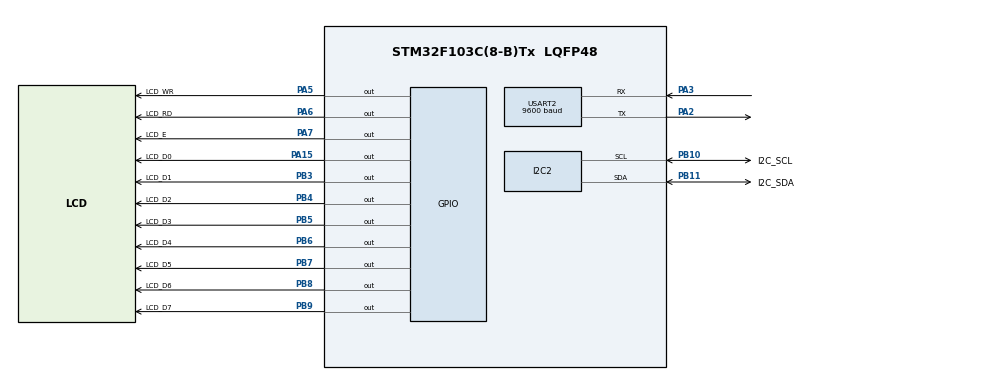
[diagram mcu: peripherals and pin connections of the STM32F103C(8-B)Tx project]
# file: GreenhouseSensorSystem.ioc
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Mcu.Family=STM32F1
Mcu.Name=STM32F103C(8-B)Tx
Mcu.Package=LQFP48
NVIC.PriorityGroup=NVIC_PRIORITYGROUP_4
NVIC.TIM1_UP_IRQn=true\:0\:0\:false\:false\:true\:false\:true
NVIC.TimeBase=TIM1_UP_IRQn
NVIC.TimeBaseIP=TIM1
PA15.GPIO_Label=LCD_D0
PA15.Signal=GPIO_Output
PA2.Mode=Asynchronous
PA2.Signal=USART2_TX
PA3.Mode=Asynchronous
PA3.Signal=USART2_RX
PA5.GPIO_Label=LCD_WR
PA5.Signal=GPIO_Output
PA6.GPIO_Label=LCD_RD
PA6.Signal=GPIO_Output
PA7.GPIO_Label=LCD_E
PA7.Signal=GPIO_Output
PB10.GPIO_Label=I2C_SCL
PB10.Mode=I2C
PB10.Signal=I2C2_SCL
PB11.GPIO_Label=I2C_SDA
PB11.Mode=I2C
PB11.Signal=I2C2_SDA
PB3.GPIO_Label=LCD_D1
PB3.Signal=GPIO_Output
PB4.GPIO_Label=LCD_D2
PB4.Signal=GPIO_Output
PB5.GPIO_Label=LCD_D3
PB5.Signal=GPIO_Output
PB6.GPIO_Label=LCD_D4
PB6.Signal=GPIO_Output
PB7.GPIO_Label=LCD_D5
PB7.Signal=GPIO_Output
PB8.GPIO_Label=LCD_D6
PB8.Signal=GPIO_Output
PB9.GPIO_Label=LCD_D7
PB9.Signal=GPIO_Output
ProjectManager.HeapSize=0x200
ProjectManager.StackSize=0x400
ProjectManager.TargetToolchain=STM32CubeIDE
RCC.APB1Freq_Value=8000000
RCC.APB2Freq_Value=8000000
USART2.BaudRate=9600
USART2.VirtualMode=VM_ASYNC
VP_SYS_VS_ND.Mode=No_Debug
VP_SYS_VS_tim1.Mode=TIM1
board=custom

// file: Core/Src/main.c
/* USER CODE BEGIN Header */
/**
  ******************************************************************************
  * @file           : main.c
  * @brief          : Main program body
  ******************************************************************************
  * @attention
  *
  * <h2><center>&copy; Copyright (c) 2020 STMicroelectronics.
  * All rights reserved.</center></h2>
  *
  * This software component is licensed by ST under BSD 3-Clause license,
  * the "License"; You may not use this file except in compliance with the
  * License. You may obtain a copy of the License at:
  *                        opensource.org/licenses/BSD-3-Clause
  *
  ******************************************************************************
  */
/* USER CODE END Header */
#include "main.h"

/* USER CODE BEGIN Includes */
#include "LCD1602.h"
#include "GY30.h"
#include "SHT31.h"
#include "HC-05.h"
#include <string.h>
#include <stdio.h>
/* USER CODE END Includes */

I2C_HandleTypeDef hi2c2;		//i2c-master handle

UART_HandleTypeDef huart2;		//uart handle
static char stringSend[128];	//string buffer ready to be send
static SHT31_DATA_T sht31Data;	//SHT31 data structure

void SystemClock_Config(void);
static void MX_GPIO_Init(void);
static void MX_I2C2_Init(void);
static void MX_USART2_UART_Init(void);

int main(void)
{

  /* MCU Configuration--------------------------------------------------------*/

  /* Reset of all peripherals, Initializes the Flash interface and the Systick. */
  HAL_Init();

  /* Configure the system clock */
  SystemClock_Config();

  /* Initialize all configured peripherals */
  MX_GPIO_Init();
  MX_I2C2_Init();
  MX_USART2_UART_Init();
  /* USER CODE BEGIN 2 */
  LCD_init();	//initialize LCD1602

  /* USER CODE END 2 */

  /* Infinite loop */
  while (1)
  {

	  LCD_writeCom(0x80|0x40);	//move cursor to position 0x40(the beginning of the second line)
	  GY30_init(GY30_ADDR_L);	//initialize GY30 sensor
	  uint16_t luminance = GY30_getData(GY30_ADDR_L);	//get GY30 data
	  LCD_show_GY30(luminance);	//show GY30 data to LCD1602

	  LCD_writeCom(0x80|0x00);	//move cursor to position 0x00(the beginning of the first line)
	  SHT31_init(SHT31_COM_N_CS, SHT31_COM_N_CS_H);	//initialize SHT31 sensor with setting consist of no-clock-stretch and high repeatibility
	  sht31Data = SHT31_readData();	//get SHT31 data
	  LCD_show_SHT31(sht31Data.temp * 1000, sht31Data.humi * 1000);	//show SHT31 data to LCD1602
	  LCD_writeCom(0x02);	//reset cursor

	  //formatted-print string
	  snprintf(stringSend, sizeof(stringSend)-1, "Temperature: %d, Humidity: %d%%, Luminance: %dlx." ,(int)sht31Data.temp, (int)sht31Data.humi, (int)luminance);

	  HC05_transmit(stringSend, strlen(stringSend));	//send text to HC05

	  HAL_Delay(500);	//delay 500 miliseconds
  }
}

void SystemClock_Config(void)
{
  RCC_OscInitTypeDef RCC_OscInitStruct = {0};
  RCC_ClkInitTypeDef RCC_ClkInitStruct = {0};

  /** Initializes the RCC Oscillators according to the specified parameters
  * in the RCC_OscInitTypeDef structure.
  */
  RCC_OscInitStruct.OscillatorType = RCC_OSCILLATORTYPE_HSI;
  RCC_OscInitStruct.HSIState = RCC_HSI_ON;
  RCC_OscInitStruct.HSICalibrationValue = RCC_HSICALIBRATION_DEFAULT;
  RCC_OscInitStruct.PLL.PLLState = RCC_PLL_NONE;
  if (HAL_RCC_OscConfig(&RCC_OscInitStruct) != HAL_OK)
  {
    Error_Handler();
  }
  /** Initializes the CPU, AHB and APB buses clocks
  */
  RCC_ClkInitStruct.ClockType = RCC_CLOCKTYPE_HCLK|RCC_CLOCKTYPE_SYSCLK
                              |RCC_CLOCKTYPE_PCLK1|RCC_CLOCKTYPE_PCLK2;
  RCC_ClkInitStruct.SYSCLKSource = RCC_SYSCLKSOURCE_HSI;
  RCC_ClkInitStruct.AHBCLKDivider = RCC_SYSCLK_DIV1;
  RCC_ClkInitStruct.APB1CLKDivider = RCC_HCLK_DIV1;
  RCC_ClkInitStruct.APB2CLKDivider = RCC_HCLK_DIV1;

  if (HAL_RCC_ClockConfig(&RCC_ClkInitStruct, FLASH_LATENCY_0) != HAL_OK)
  {
    Error_Handler();
  }
}

static void MX_I2C2_Init(void)
{

  hi2c2.Instance = I2C2;
  hi2c2.Init.ClockSpeed = 100000;
  hi2c2.Init.DutyCycle = I2C_DUTYCYCLE_2;
  hi2c2.Init.OwnAddress1 = 0;
  hi2c2.Init.AddressingMode = I2C_ADDRESSINGMODE_7BIT;
  hi2c2.Init.DualAddressMode = I2C_DUALADDRESS_DISABLE;
  hi2c2.Init.OwnAddress2 = 0;
  hi2c2.Init.GeneralCallMode = I2C_GENERALCALL_DISABLE;
  hi2c2.Init.NoStretchMode = I2C_NOSTRETCH_DISABLE;
  if (HAL_I2C_Init(&hi2c2) != HAL_OK)
  {
    Error_Handler();
  }

}

static void MX_USART2_UART_Init(void)
{

  huart2.Instance = USART2;
  huart2.Init.BaudRate = 9600;
  huart2.Init.WordLength = UART_WORDLENGTH_8B;
  huart2.Init.StopBits = UART_STOPBITS_1;
  huart2.Init.Parity = UART_PARITY_NONE;
  huart2.Init.Mode = UART_MODE_TX_RX;
  huart2.Init.HwFlowCtl = UART_HWCONTROL_NONE;
  huart2.Init.OverSampling = UART_OVERSAMPLING_16;
  if (HAL_UART_Init(&huart2) != HAL_OK)
  {
    Error_Handler();
  }

}

static void MX_GPIO_Init(void)
{
  GPIO_InitTypeDef GPIO_InitStruct = {0};

  /* GPIO Ports Clock Enable */
  __HAL_RCC_GPIOA_CLK_ENABLE();
  __HAL_RCC_GPIOB_CLK_ENABLE();

  /*Configure GPIO pin Output Level */
  HAL_GPIO_WritePin(GPIOA, LCD_WR_Pin|LCD_RD_Pin|LCD_E_Pin|LCD_D0_Pin, GPIO_PIN_RESET);

  /*Configure GPIO pin Output Level */
  HAL_GPIO_WritePin(GPIOB, LCD_D1_Pin|LCD_D2_Pin|LCD_D3_Pin|LCD_D4_Pin
                          |LCD_D5_Pin|LCD_D6_Pin|LCD_D7_Pin, GPIO_PIN_RESET);

  /*Configure GPIO pins : LCD_WR_Pin LCD_RD_Pin LCD_E_Pin LCD_D0_Pin */
  GPIO_InitStruct.Pin = LCD_WR_Pin|LCD_RD_Pin|LCD_E_Pin|LCD_D0_Pin;
  GPIO_InitStruct.Mode = GPIO_MODE_OUTPUT_PP;
  GPIO_InitStruct.Pull = GPIO_NOPULL;
  GPIO_InitStruct.Speed = GPIO_SPEED_FREQ_LOW;
  HAL_GPIO_Init(GPIOA, &GPIO_InitStruct);

  /*Configure GPIO pins : LCD_D1_Pin LCD_D2_Pin LCD_D3_Pin LCD_D4_Pin
                           LCD_D5_Pin LCD_D6_Pin LCD_D7_Pin */
  GPIO_InitStruct.Pin = LCD_D1_Pin|LCD_D2_Pin|LCD_D3_Pin|LCD_D4_Pin
                          |LCD_D5_Pin|LCD_D6_Pin|LCD_D7_Pin;
  GPIO_InitStruct.Mode = GPIO_MODE_OUTPUT_PP;
  GPIO_InitStruct.Pull = GPIO_NOPULL;
  GPIO_InitStruct.Speed = GPIO_SPEED_FREQ_LOW;
  HAL_GPIO_Init(GPIOB, &GPIO_InitStruct);

}

 /**
  * @brief  Period elapsed callback in non blocking mode
  * @note   This function is called  when TIM1 interrupt took place, inside
  * HAL_TIM_IRQHandler(). It makes a direct call to HAL_IncTick() to increment
  * a global variable "uwTick" used as application time base.
  * @param  htim : TIM handle
  * @retval None
  */
void HAL_TIM_PeriodElapsedCallback(TIM_HandleTypeDef *htim)
{
  if (htim->Instance == TIM1) {
    HAL_IncTick();
  }
}

void Error_Handler(void)
{
}

/************************ (C) COPYRIGHT STMicroelectronics *****END OF FILE****/
